# MKW38A4 register map
Vendor: NXP Semiconductors; Series: Kinetis_W; File version: 1.6
CPU: CM0PLUS r0p0, little endian, no MPU, no FPU, VTOR, 2 interrupt priority bits
Registers are 32-bit, read-write, no defined reset value unless marked. A register's access mark holds for its fields unless they carry their own. Offsets are from the block's base; [hi:lo] are bit positions; {n}, {i} and the like mark numbered series.

## XCVR_TX_DIG
Base 0x40087700
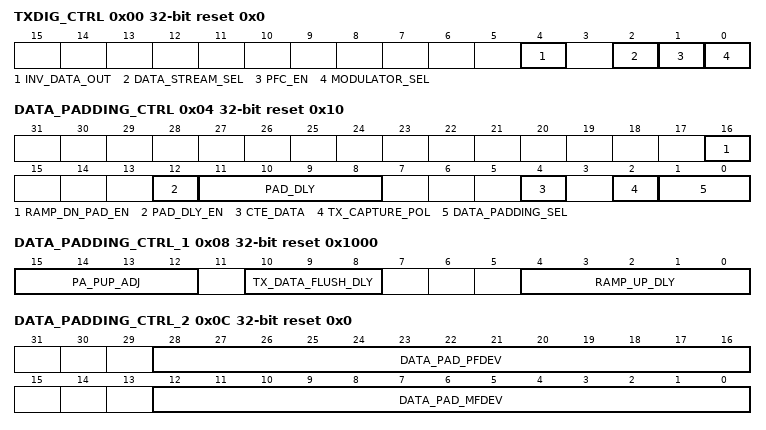
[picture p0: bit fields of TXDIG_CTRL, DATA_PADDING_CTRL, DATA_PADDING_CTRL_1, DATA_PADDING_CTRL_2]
0x00 TXDIG_CTRL reset 0x0
  [4] INV_DATA_OUT, [2] DATA_STREAM_SEL, [1] PFC_EN, [0] MODULATOR_SEL
0x04 DATA_PADDING_CTRL reset 0x10
  [16] RAMP_DN_PAD_EN, [12] PAD_DLY_EN, [11:8] PAD_DLY, [4] CTE_DATA, [2] TX_CAPTURE_POL, [1:0] DATA_PADDING_SEL
0x08 DATA_PADDING_CTRL_1 reset 0x1000
  [15:12] PA_PUP_ADJ, [10:8] TX_DATA_FLUSH_DLY, [4:0] RAMP_UP_DLY
0x0C DATA_PADDING_CTRL_2 reset 0x0
  [28:16] DATA_PAD_PFDEV, [12:0] DATA_PAD_MFDEV
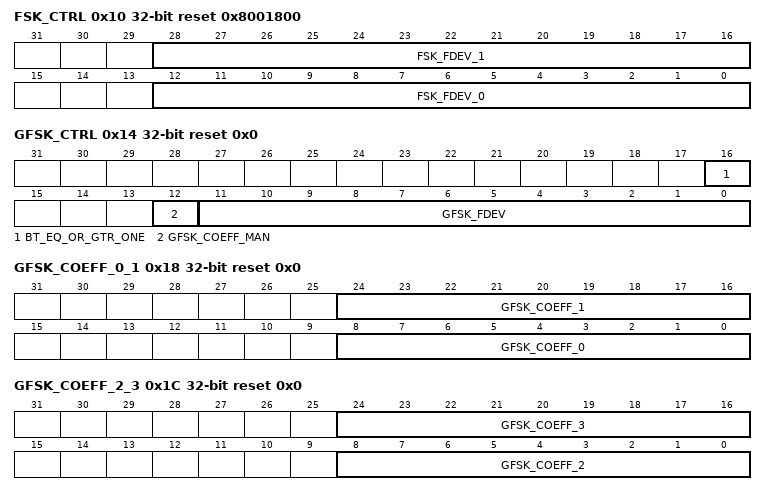
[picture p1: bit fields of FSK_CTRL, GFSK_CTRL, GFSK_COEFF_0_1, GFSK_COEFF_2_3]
0x10 FSK_CTRL reset 0x8001800
  [28:16] FSK_FDEV_1, [12:0] FSK_FDEV_0
0x14 GFSK_CTRL reset 0x0
  [16] BT_EQ_OR_GTR_ONE, [12] GFSK_COEFF_MAN, [11:0] GFSK_FDEV
0x18 GFSK_COEFF_0_1 reset 0x0
  [24:16] GFSK_COEFF_1, [8:0] GFSK_COEFF_0
0x1C GFSK_COEFF_2_3 reset 0x0
  [24:16] GFSK_COEFF_3, [8:0] GFSK_COEFF_2
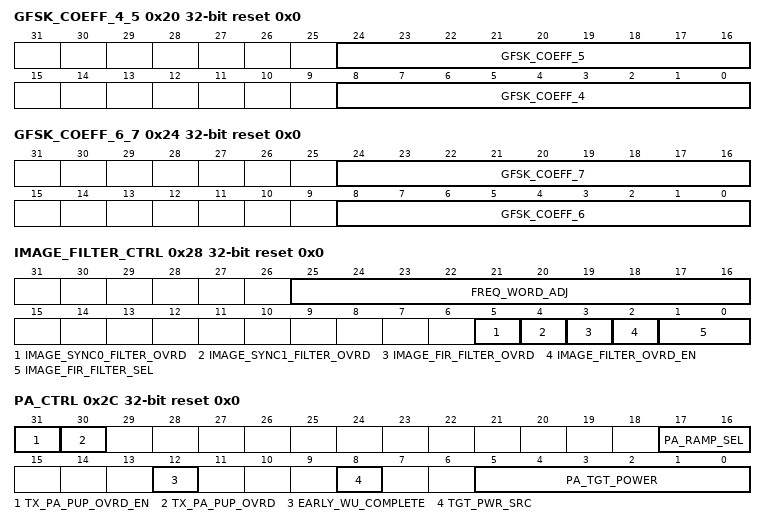
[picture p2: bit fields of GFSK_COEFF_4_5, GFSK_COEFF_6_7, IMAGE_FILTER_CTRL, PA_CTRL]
0x20 GFSK_COEFF_4_5 reset 0x0
  [24:16] GFSK_COEFF_5, [8:0] GFSK_COEFF_4
0x24 GFSK_COEFF_6_7 reset 0x0
  [24:16] GFSK_COEFF_7, [8:0] GFSK_COEFF_6
0x28 IMAGE_FILTER_CTRL reset 0x0
  [25:16] FREQ_WORD_ADJ, [5] IMAGE_SYNC0_FILTER_OVRD, [4] IMAGE_SYNC1_FILTER_OVRD, [3] IMAGE_FIR_FILTER_OVRD, [2] IMAGE_FILTER_OVRD_EN, [1:0] IMAGE_FIR_FILTER_SEL
0x2C PA_CTRL reset 0x0
  [31] TX_PA_PUP_OVRD_EN, [30] TX_PA_PUP_OVRD, [17:16] PA_RAMP_SEL, [12] EARLY_WU_COMPLETE, [8] TGT_PWR_SRC, [5:0] PA_TGT_POWER
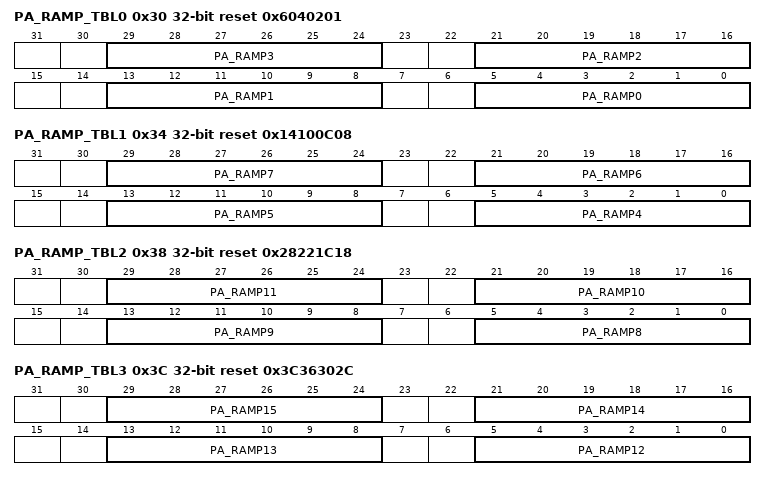
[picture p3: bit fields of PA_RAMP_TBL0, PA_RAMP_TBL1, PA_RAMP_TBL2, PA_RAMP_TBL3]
0x30 PA_RAMP_TBL0 reset 0x6040201
  [8n+5:8n] PA_RAMP{n} (n=0..3)
0x34 PA_RAMP_TBL1 reset 0x14100C08
  [8n-27:8n-32] PA_RAMP{n} (n=4..7)
0x38 PA_RAMP_TBL2 reset 0x28221C18
  [8n-59:8n-64] PA_RAMP{n} (n=8..11)
0x3C PA_RAMP_TBL3 reset 0x3C36302C
  [8n-91:8n-96] PA_RAMP{n} (n=12..15)
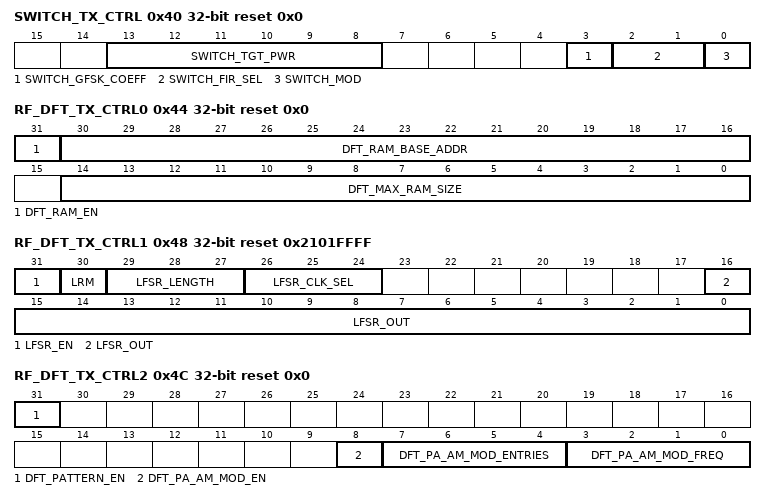
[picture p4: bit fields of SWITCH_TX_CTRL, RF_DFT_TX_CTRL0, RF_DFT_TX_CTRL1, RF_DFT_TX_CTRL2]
0x40 SWITCH_TX_CTRL reset 0x0
  [13:8] SWITCH_TGT_PWR, [3] SWITCH_GFSK_COEFF, [2:1] SWITCH_FIR_SEL, [0] SWITCH_MOD
0x44 RF_DFT_TX_CTRL0 reset 0x0
  [31] DFT_RAM_EN, [30:16] DFT_RAM_BASE_ADDR, [14:0] DFT_MAX_RAM_SIZE
0x48 RF_DFT_TX_CTRL1 reset 0x2101FFFF
  [31] LFSR_EN, [30] LRM, [29:27] LFSR_LENGTH, [26:24] LFSR_CLK_SEL, [16:0] LFSR_OUT ro
0x4C RF_DFT_TX_CTRL2 reset 0x0
  [31] DFT_PATTERN_EN, [8] DFT_PA_AM_MOD_EN, [7:4] DFT_PA_AM_MOD_ENTRIES, [3:0] DFT_PA_AM_MOD_FREQ
0x50 RF_DFT_PATTERN reset 0x0
  [31:0] DFT_MOD_PATTERN
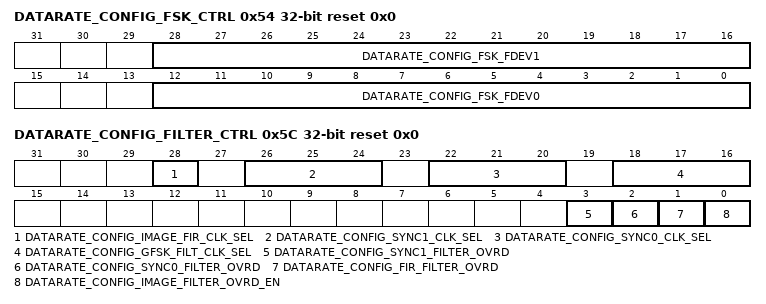
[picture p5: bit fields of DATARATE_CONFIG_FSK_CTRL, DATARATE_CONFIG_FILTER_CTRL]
0x54 DATARATE_CONFIG_FSK_CTRL reset 0x0
  [28:16] DATARATE_CONFIG_FSK_FDEV1 — DATARATE_CONFIG_DATA_PAD_PFDEV
  [12:0] DATARATE_CONFIG_FSK_FDEV0 — DATARATE_CONFIG_DATA_PAD_MFDEV
0x58 DATARATE_CONFIG_GFSK_CTRL reset 0x0
  [11:0] DATARATE_CONFIG_GFSK_FDEV
0x5C DATARATE_CONFIG_FILTER_CTRL reset 0x0
  [28] DATARATE_CONFIG_IMAGE_FIR_CLK_SEL
  [26:24] DATARATE_CONFIG_SYNC1_CLK_SEL — DATARATE_CONFIG_IMAGE_SYNC1_CLK_SEL
  [22:20] DATARATE_CONFIG_SYNC0_CLK_SEL — DATARATE_CONFIG_IMAGE_SYNC0_CLK_SEL
  [18:16] DATARATE_CONFIG_GFSK_FILT_CLK_SEL
  [3] DATARATE_CONFIG_SYNC1_FILTER_OVRD
  [2] DATARATE_CONFIG_SYNC0_FILTER_OVRD
  [1] DATARATE_CONFIG_FIR_FILTER_OVRD
  [0] DATARATE_CONFIG_IMAGE_FILTER_OVRD_EN

## TX_PACKET_RAM — RADIO_PACKET_RAM
Base 0x40088000
{0x0+4i} PACKET_RAM_{i} (i=0..2559) — Shared Packet RAM for multiple Link Layer usage.
  [31:0] RAM — One entry in the packet RAM

## RX_PACKET_RAM — RADIO_PACKET_RAM
Base 0x4008B000
Registers as TX_PACKET_RAM, without PACKET_RAM_{n} (n=1888..2559).

## GPIOA — General Purpose Input/Output
Base 0x400FF000; register names take the prefix GPIOA_
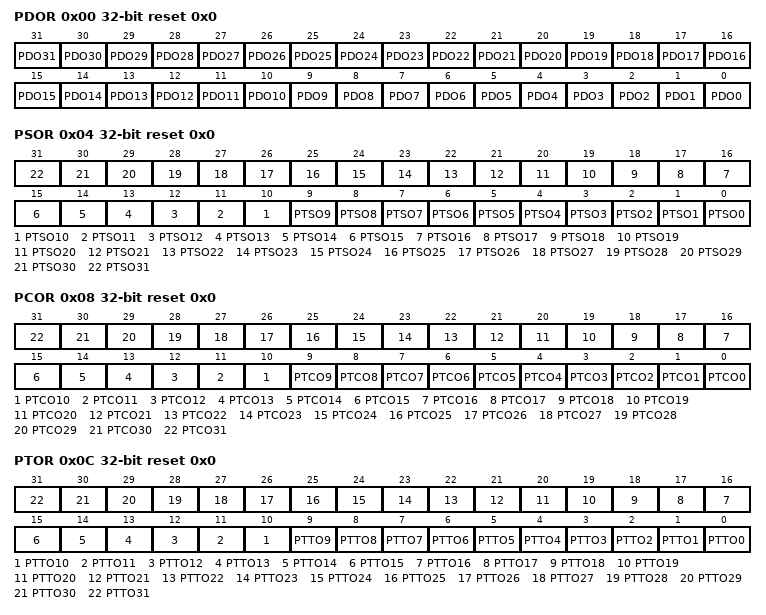
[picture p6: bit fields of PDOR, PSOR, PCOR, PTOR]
0x00 PDOR reset 0x0 — Port Data Output Register
  [all] fields
    0=Logic level 0 is driven on pin, provided pin is configured for general-purpose output; 1=Logic level 1 is driven on pin, provided pin is configured for general-purpose output
  [n] PDO{n} (n=0..31) — Port Data Output
0x04 PSOR reset 0x0 — Port Set Output Register
  [all] fields
    0=Corresponding bit in PDORn does not change; 1=Corresponding bit in PDORn is set to logic 1
  [n] PTSO{n} (n=0..31) — Port Set Output
0x08 PCOR reset 0x0 — Port Clear Output Register
  [all] fields
    0=Corresponding bit in PDORn does not change; 1=Corresponding bit in PDORn is cleared to logic 0
  [n] PTCO{n} (n=0..31) — Port Clear Output
0x0C PTOR reset 0x0 — Port Toggle Output Register
  [all] fields
    0=Corresponding bit in PDORn does not change; 1=Corresponding bit in PDORn is set to the inverse of its existing logic state
  [n] PTTO{n} (n=0..31) — Port Toggle Output
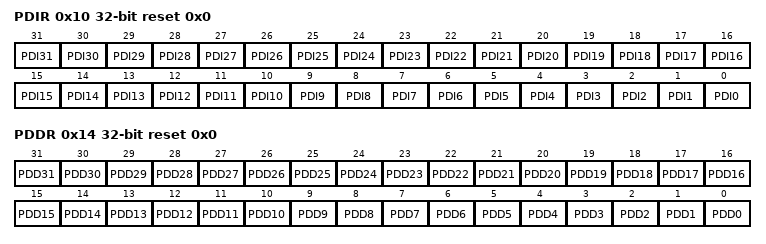
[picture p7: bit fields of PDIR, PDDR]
0x10 PDIR ro reset 0x0 — Port Data Input Register
  [all] fields
    0=Pin logic level is logic 0, or is not configured for use by digital function; 1=Pin logic level is logic 1
  [n] PDI{n} (n=0..31) — Port Data Input
0x14 PDDR reset 0x0 — Port Data Direction Register
  [all] fields
    0=Pin is configured as general-purpose input, for the GPIO function; 1=Pin is configured as general-purpose output, for the GPIO function
  [n] PDD{n} (n=0..31) — Port Data Direction

## GPIOB — General Purpose Input/Output
Base 0x400FF040; register names take the prefix GPIOB_
Registers as GPIOA.

## GPIOC — General Purpose Input/Output
Base 0x400FF080; register names take the prefix GPIOC_
Registers as GPIOA.
